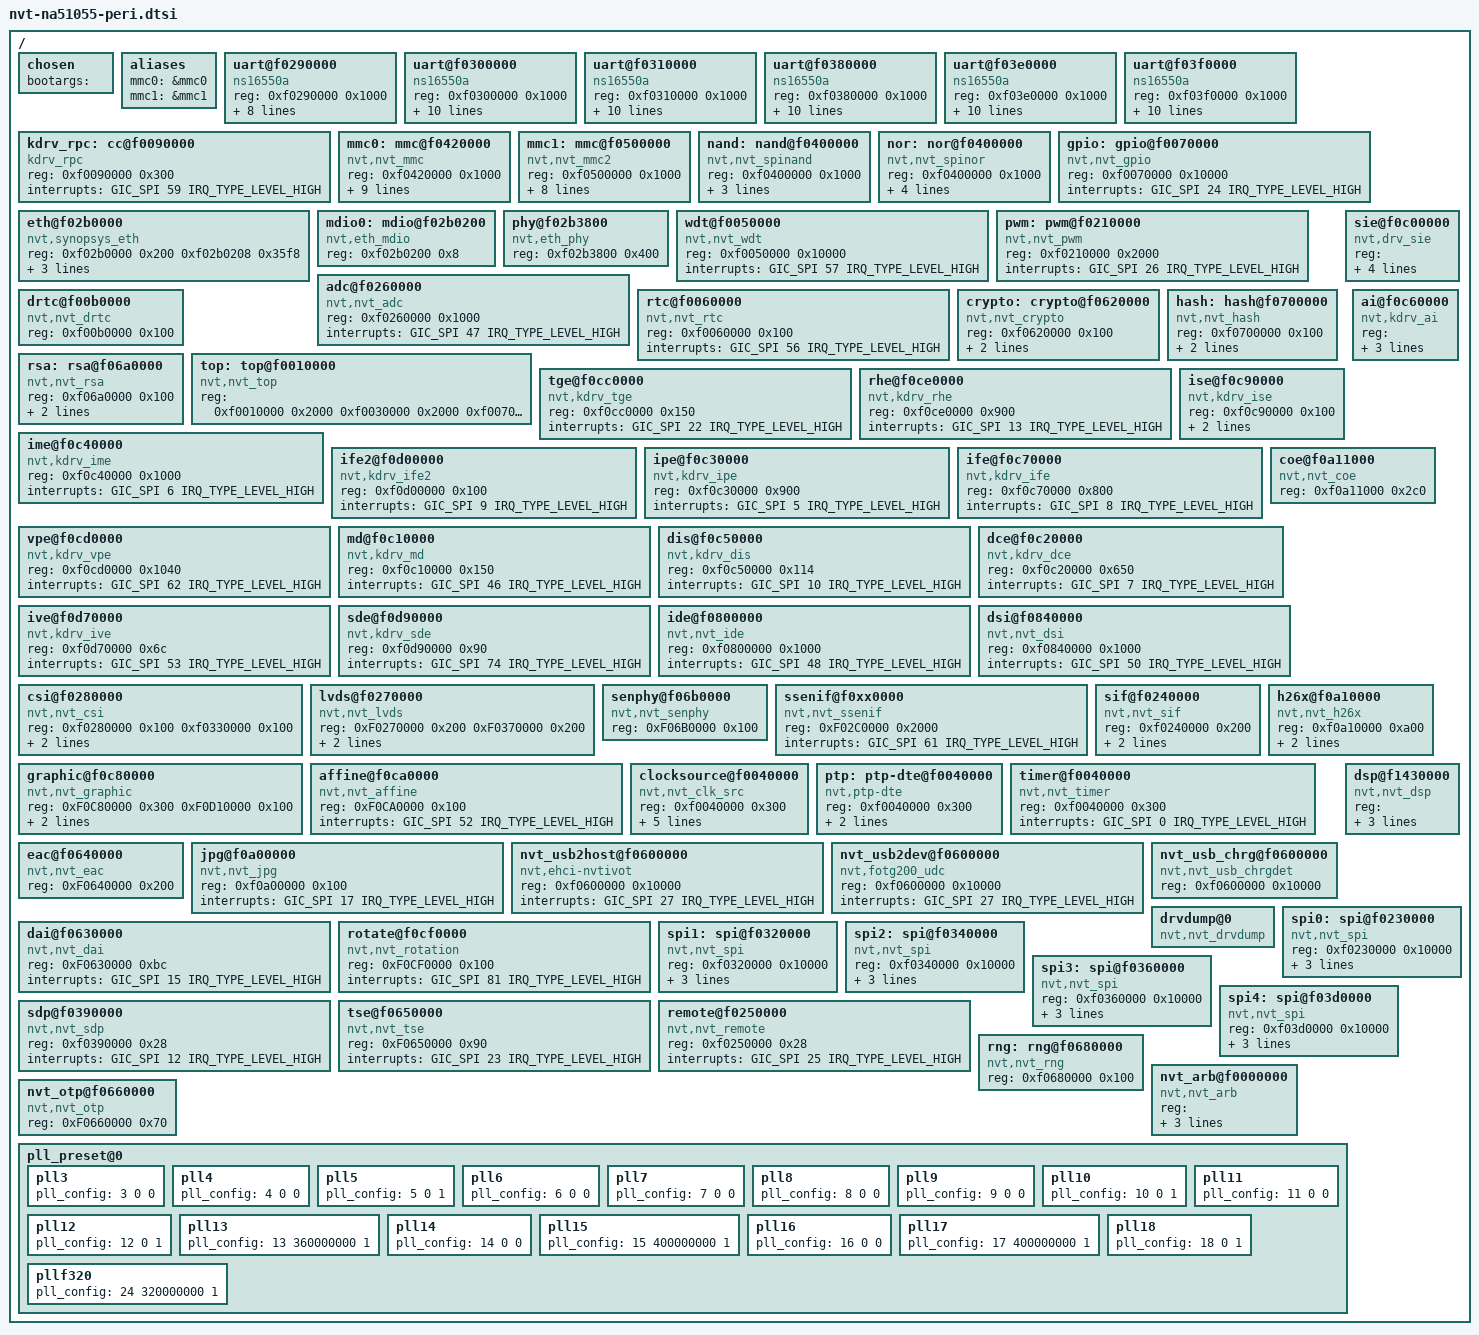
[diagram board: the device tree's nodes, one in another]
/*
 * Novatek Ltd. NA51055 BSP part of dts
 *
 * Cortex-A9
 *
 */


#include <dt-bindings/gpio/nvt-gpio.h>
#include "nvt-na51055-basic.dtsi"

/ {
	chosen {
		bootargs = " ";
	};

	aliases {
		mmc0 = &mmc0;	/* Fixed to mmcblk0 for sdio1 */
		mmc1 = &mmc1;	/* Fixed to mmcblk1 for sdio2 */
	};

	uart@f0290000 {
		compatible = "ns16550a";
		reg = <0xf0290000 0x1000>;
		interrupts = <GIC_SPI 43 IRQ_TYPE_LEVEL_HIGH>;
		baud = <115200>;
		reg-shift = <2>;
		reg-io-width = <4>;
		no-loopback-test = <1>;
		clock-frequency = <24000000>;
		fifo-size = <64>;	/* For platform 520 is 16 and platform 528 is 64 */
		uart_id = <0>;
	};

	uart@f0300000 {
		compatible = "ns16550a";
		reg = <0xf0300000 0x1000>;
		interrupts = <GIC_SPI 44 IRQ_TYPE_LEVEL_HIGH>;
		baud = <115200>;
		reg-shift = <2>;
		reg-io-width = <4>;
		no-loopback-test = <1>;
		clock-frequency = <48000000>;
		fifo-size = <64>;
		hw_flowctrl = <0>;
		rx_trig_level = <1>;
		uart_id = <1>;
	};

	uart@f0310000 {
		compatible = "ns16550a";
		reg = <0xf0310000 0x1000>;
		interrupts = <GIC_SPI 45 IRQ_TYPE_LEVEL_HIGH>;
		baud = <115200>;
		reg-shift = <2>;
		reg-io-width = <4>;
		no-loopback-test = <1>;
		clock-frequency = <48000000>;
		fifo-size = <64>;
		hw_flowctrl = <0>;
		rx_trig_level = <1>;
		uart_id = <2>;
	};

	uart@f0380000 {
		compatible = "ns16550a";
		reg = <0xf0380000 0x1000>;
		interrupts = <GIC_SPI 63 IRQ_TYPE_LEVEL_HIGH>;
		baud = <115200>;
		reg-shift = <2>;
		reg-io-width = <4>;
		no-loopback-test = <1>;
		clock-frequency = <48000000>;
		fifo-size = <64>;
		hw_flowctrl = <0>;
		rx_trig_level = <1>;
		uart_id = <3>;
	};

	uart@f03e0000 {
		compatible = "ns16550a";
		reg = <0xf03e0000 0x1000>;
		interrupts = <GIC_SPI 64 IRQ_TYPE_LEVEL_HIGH>;
		baud = <115200>;
		reg-shift = <2>;
		reg-io-width = <4>;
		no-loopback-test = <1>;
		clock-frequency = <48000000>;
		fifo-size = <64>;
		hw_flowctrl = <0>;
		rx_trig_level = <1>;
		uart_id = <4>;
	};

	uart@f03f0000 {
		compatible = "ns16550a";
		reg = <0xf03f0000 0x1000>;
		interrupts = <GIC_SPI 65 IRQ_TYPE_LEVEL_HIGH>;
		baud = <115200>;
		reg-shift = <2>;
		reg-io-width = <4>;
		no-loopback-test = <1>;
		clock-frequency = <48000000>;
		fifo-size = <64>;
		hw_flowctrl = <0>;
		rx_trig_level = <1>;
		uart_id = <5>;
	};

	kdrv_rpc: cc@f0090000 {
		compatible = "kdrv_rpc";
		reg = <0xf0090000 0x300>;
		interrupts = <GIC_SPI 59 IRQ_TYPE_LEVEL_HIGH>;
	};

	mmc0: mmc@f0420000 {
		compatible = "nvt,nvt_mmc";
		reg = <0xf0420000 0x1000>;
		interrupts = <GIC_SPI 30 IRQ_TYPE_LEVEL_HIGH>;
		max-frequency = <48000000>;
		voltage-switch = <0>;
		max-voltage = <3300>;
		bus-width = <4>;
		neg-sample-edge = <0>;
		driving = <15 15 15 20 15 15 25 25 25 25 25 25>;
		cd_gpio = <P_GPIO(17) GPIO_FALLING_EDGE GPIO_POLLING>;
		/*card_power_gpio = <P_GPIO(0) GPIO_LOW>;*/
		/*ro_gpio = <D_GPIO(1) GPIO_RISING_EDGE GPIO_POLLING>;*/
		/*power_en = <D_GPIO(2) GPIO_RISING_EDGE>;*/
	};

	mmc1: mmc@f0500000 {
		compatible = "nvt,nvt_mmc2";
		reg = <0xf0500000 0x1000>;
		interrupts = <GIC_SPI 31 IRQ_TYPE_LEVEL_HIGH>;
		max-frequency = <48000000>;
		voltage-switch = <0>;
		max-voltage = <3300>;
		bus-width = <4>;
		neg-sample-edge = <0>;
		driving = <15 8 8 15 8 8 15 8 8 15 8 8>;
		cd_gpio = <0 GPIO_FALLING_EDGE GPIO_INTERRUPT>;
		/*ro_gpio = <D_GPIO(3) GPIO_RISING_EDGE GPIO_POLLING>;*/
		/*power_en = <D_GPIO(4) GPIO_RISING_EDGE>;*/
	};

	nand: nand@f0400000 {
		#address-cells = <2>;
		#size-cells = <2>;
		compatible = "nvt,nvt_spinand";
		reg = <0xf0400000 0x1000>;
		interrupts = <GIC_SPI 29 IRQ_TYPE_LEVEL_HIGH>;
		clock-frequency = <80000000>;
		nvt-devname = "spi_nand.0";
	};

	nor: nor@f0400000 {
		#address-cells = <2>;
		#size-cells = <2>;
		compatible = "nvt,nvt_spinor";
		reg = <0xf0400000 0x1000>;
		interrupts = <GIC_SPI 29 IRQ_TYPE_LEVEL_HIGH>;
		clock-frequency = <48000000>;
		nvt-devname = "spi_nor.0";
		trace-stdtable = <1>;
	};

	gpio: gpio@f0070000 {
		compatible = "nvt,nvt_gpio";
		reg = <0xf0070000 0x10000>;
		interrupts = <GIC_SPI 24 IRQ_TYPE_LEVEL_HIGH>;
		#gpio-cells = <2>;
	};

	eth@f02b0000 {
		compatible = "nvt,synopsys_eth";
		reg = <0xf02b0000 0x200
		       0xf02b0208 0x35f8>;
		interrupts = <GIC_SPI 34 IRQ_TYPE_LEVEL_HIGH>;
		sp-clk = <0>;
		ref-clk-out = <0>;
	};

	mdio0: mdio@f02b0200{
		compatible = "nvt,eth_mdio";
		reg = <0xf02b0200 0x8>;
	};

	phy@f02b3800 {
		compatible = "nvt,eth_phy";
		reg = <0xf02b3800 0x400>;
	};

	wdt@f0050000 {
		compatible = "nvt,nvt_wdt";
		reg = <0xf0050000 0x10000>;
		interrupts = <GIC_SPI 57 IRQ_TYPE_LEVEL_HIGH>;
	};

	pwm: pwm@f0210000 {
		compatible = "nvt,nvt_pwm";
		reg = <0xf0210000 0x2000>;
		interrupts = <GIC_SPI 26 IRQ_TYPE_LEVEL_HIGH>;
	};

	adc@f0260000 {
		compatible = "nvt,nvt_adc";
		reg = <0xf0260000 0x1000>;
		interrupts = <GIC_SPI 47 IRQ_TYPE_LEVEL_HIGH>;
		#io-channel-cells = <1>;
	};

	rtc@f0060000 {
		compatible = "nvt,nvt_rtc";
		reg = <0xf0060000 0x100>;
		interrupts = <GIC_SPI 56 IRQ_TYPE_LEVEL_HIGH>;
	};

    drtc@f00b0000 {
        compatible = "nvt,nvt_drtc";
        reg = <0xf00b0000 0x100>;
    };

    crypto: crypto@f0620000 {
        compatible = "nvt,nvt_crypto";
        reg = <0xf0620000 0x100>;
        interrupts = <0 38 IRQ_TYPE_LEVEL_HIGH>;
        mclk = <1>;
    };

    hash: hash@f0700000 {
        compatible = "nvt,nvt_hash";
        reg = <0xf0700000 0x100>;
        interrupts = <0 28 IRQ_TYPE_LEVEL_HIGH>;
        mclk = <1>;
    };

    rsa: rsa@f06a0000 {
        compatible = "nvt,nvt_rsa";
        reg = <0xf06a0000 0x100>;
        interrupts = <0 20 IRQ_TYPE_LEVEL_HIGH>;
        mclk = <1>;
    };

	top: top@f0010000 {
		compatible = "nvt,nvt_top";
		reg = <0xf0010000 0x2000
			0xf0030000 0x2000
			0xf0070000 0x10000>;
	};

	sie@f0c00000 {
		compatible = "nvt,drv_sie";
		reg = <0xf0c00000 0x900
			0xf0d20000 0x900
			0xF0D30000 0x900
			0xF0D40000 0x900
			0xF0D80000 0x900>;
		interrupts = <GIC_SPI 1 IRQ_TYPE_LEVEL_HIGH
					GIC_SPI 2 IRQ_TYPE_LEVEL_HIGH
					GIC_SPI 3 IRQ_TYPE_LEVEL_HIGH
					GIC_SPI 59 IRQ_TYPE_LEVEL_HIGH
					GIC_SPI 61 IRQ_TYPE_LEVEL_HIGH>;
		/*sensor_freq = <37125000>;*/
		power_saving = <0>;  /* 0:using default pll_10,  1: using fix480m, run 240MHz,  2: using fix480m, run 120MHz */
	};

	tge@f0cc0000 {
		compatible = "nvt,kdrv_tge";
		reg = <0xf0cc0000 0x150>;
		interrupts = <GIC_SPI 22 IRQ_TYPE_LEVEL_HIGH>;
	};

	rhe@f0ce0000 {
		compatible = "nvt,kdrv_rhe";
		reg = <0xf0ce0000 0x900>;
		interrupts = <GIC_SPI 13 IRQ_TYPE_LEVEL_HIGH>;
	};

	ime@f0c40000 {
		compatible = "nvt,kdrv_ime";
		reg = <0xf0c40000 0x1000>;
		interrupts = <GIC_SPI 6 IRQ_TYPE_LEVEL_HIGH>;
	};

	ife2@f0d00000 {
		compatible = "nvt,kdrv_ife2";
		reg = <0xf0d00000 0x100>;
		interrupts = <GIC_SPI 9 IRQ_TYPE_LEVEL_HIGH>;
	};

	ise@f0c90000 {
		compatible = "nvt,kdrv_ise";
		reg = <0xf0c90000 0x100>;
		interrupts = <GIC_SPI 21 IRQ_TYPE_LEVEL_HIGH
					GIC_SPI 85 IRQ_TYPE_LEVEL_HIGH>;
	};

	ipe@f0c30000 {
		compatible = "nvt,kdrv_ipe";
		reg = <0xf0c30000 0x900>;
		interrupts = <GIC_SPI 5 IRQ_TYPE_LEVEL_HIGH>;
	};

	ife@f0c70000 {
		compatible = "nvt,kdrv_ife";
		reg = <0xf0c70000 0x800>;
		interrupts = <GIC_SPI 8 IRQ_TYPE_LEVEL_HIGH>;
	};
  
	vpe@f0cd0000 {
		compatible = "nvt,kdrv_vpe";
		reg = <0xf0cd0000 0x1040>;
		interrupts = <GIC_SPI 62 IRQ_TYPE_LEVEL_HIGH>;
	};

	ai@f0c60000 {
		compatible = "nvt,kdrv_ai";
		reg = <0xf0c60000 0x1cc
			   0xf0d50000 0x94
			   0xf0d60000 0x200
			   0xf0cb0000 0x200>;
		interrupts = <GIC_SPI 14 IRQ_TYPE_LEVEL_HIGH
					  GIC_SPI 13 IRQ_TYPE_LEVEL_HIGH
					  GIC_SPI 49 IRQ_TYPE_LEVEL_HIGH
					  GIC_SPI 11 IRQ_TYPE_LEVEL_HIGH>;
    };

	md@f0c10000 {
		compatible = "nvt,kdrv_md";
		reg = <0xf0c10000 0x150>;
		interrupts = <GIC_SPI 46 IRQ_TYPE_LEVEL_HIGH>;
	};
		dis@f0c50000 {
                compatible = "nvt,kdrv_dis";
                reg = <0xf0c50000 0x114>;
                interrupts = <GIC_SPI 10 IRQ_TYPE_LEVEL_HIGH>;
	};

	coe@f0a11000 {
		compatible = "nvt,nvt_coe";
		reg = <0xf0a11000 0x2c0>;
	};

	dce@f0c20000 {
		compatible = "nvt,kdrv_dce";
		reg = <0xf0c20000 0x650>;
		interrupts = <GIC_SPI 7 IRQ_TYPE_LEVEL_HIGH>;
	};

	ive@f0d70000 {
		compatible = "nvt,kdrv_ive";
		reg = <0xf0d70000 0x6c>;
		interrupts = <GIC_SPI 53 IRQ_TYPE_LEVEL_HIGH>;
	};

	sde@f0d90000 {
		compatible = "nvt,kdrv_sde";
		reg = <0xf0d90000 0x90>;
		interrupts = <GIC_SPI 74 IRQ_TYPE_LEVEL_HIGH>;
	};

        ide@f0800000 {
                compatible = "nvt,nvt_ide";
                reg = <0xf0800000 0x1000>;
                interrupts = <GIC_SPI 48 IRQ_TYPE_LEVEL_HIGH>;
        };

	dsi@f0840000 {
		compatible = "nvt,nvt_dsi";
		reg = <0xf0840000 0x1000>;
		interrupts = <GIC_SPI 50 IRQ_TYPE_LEVEL_HIGH>;
	};

	csi@f0280000 {
		compatible = "nvt,nvt_csi";
		reg = <0xf0280000 0x100
				0xf0330000 0x100>;
		interrupts = <GIC_SPI 54 IRQ_TYPE_LEVEL_HIGH
					GIC_SPI 55 IRQ_TYPE_LEVEL_HIGH>;
	};

	lvds@f0270000 {
		compatible = "nvt,nvt_lvds";
		reg = <0xF0270000 0x200
				0xF0370000 0x200>;
		interrupts = <GIC_SPI 54 IRQ_TYPE_LEVEL_HIGH
					GIC_SPI 55 IRQ_TYPE_LEVEL_HIGH>;
	};

	senphy@f06b0000 {
		compatible = "nvt,nvt_senphy";
		reg = <0xF06B0000 0x100>;
	};

	ssenif@f0xx0000 {
		compatible = "nvt,nvt_ssenif";
		reg = <0xF02C0000 0x2000>;
		interrupts = <GIC_SPI 61 IRQ_TYPE_LEVEL_HIGH>;
	};

	sif@f0240000 {
		compatible = "nvt,nvt_sif";
		reg = <0xf0240000 0x200>;
		interrupts = <GIC_SPI 40 IRQ_TYPE_LEVEL_HIGH>;
		clock-frequency = <1000000>;
	};

	graphic@f0c80000 {
		compatible = "nvt,nvt_graphic";
		reg = <0xF0C80000 0x300
			0xF0D10000 0x100>;
		interrupts = <GIC_SPI 18 IRQ_TYPE_LEVEL_HIGH
					GIC_SPI 19 IRQ_TYPE_LEVEL_HIGH>;
	};

	affine@f0ca0000 {
		compatible = "nvt,nvt_affine";
		reg = <0xF0CA0000 0x100>;
		interrupts = <GIC_SPI 52 IRQ_TYPE_LEVEL_HIGH>;
	};

	h26x@f0a10000 {
		compatible = "nvt,nvt_h26x";
		reg = <0xf0a10000 0xa00>;
		interrupts = <GIC_SPI 16 IRQ_TYPE_LEVEL_HIGH>;
		power_saving = <1>;	/* 0:using default pllf320, 1:using pll15, 2:using pll13*/
	};

	clocksource@f0040000 {
		compatible = "nvt,nvt_clk_src";
		reg = <0xf0040000 0x300>;
		interrupts = <GIC_SPI 0 IRQ_TYPE_LEVEL_HIGH>;
		clock-frequency1 = <3000000>;
		clock-frequency2 = <3000000>;
		clksrc = <1>;
		bits = <32>;
		clock-names = "f0040000.timer";
	};

	ptp: ptp-dte@f0040000 {
		compatible = "nvt,ptp-dte";
		reg = <0xf0040000 0x300>;
		clock-frequency = <3000000>;
		interrupts = <GIC_SPI 0 IRQ_TYPE_LEVEL_HIGH>;
	};

	timer@f0040000 {
		compatible = "nvt,nvt_timer";
		reg = <0xf0040000 0x300>;
		interrupts = <GIC_SPI 0 IRQ_TYPE_LEVEL_HIGH>;
	};

	eac@f0640000 {
		compatible = "nvt,nvt_eac";
		reg = <0xF0640000 0x200>;
	};

	jpg@f0a00000 {
		compatible = "nvt,nvt_jpg";
		reg = <0xf0a00000 0x100>;
		interrupts = <GIC_SPI 17 IRQ_TYPE_LEVEL_HIGH>;
	};

	nvt_usb2host@f0600000 {
		compatible = "nvt,ehci-nvtivot";
		reg = <0xf0600000 0x10000>;
		interrupts = <GIC_SPI 27 IRQ_TYPE_LEVEL_HIGH>;
	};

	nvt_usb2dev@f0600000 {
		compatible = "nvt,fotg200_udc";
		reg = <0xf0600000 0x10000>;
		interrupts = <GIC_SPI 27 IRQ_TYPE_LEVEL_HIGH>;
	};

	nvt_usb_chrg@f0600000 {
		compatible = "nvt,nvt_usb_chrgdet";
		reg = <0xf0600000 0x10000>;
	};

	dai@f0630000 {
		compatible = "nvt,nvt_dai";
		reg = <0xF0630000 0xbc>;
		interrupts = <GIC_SPI 15 IRQ_TYPE_LEVEL_HIGH>;
	};

	rotate@f0cf0000 {
		compatible = "nvt,nvt_rotation";
		reg = <0xF0CF0000 0x100>;
		interrupts = <GIC_SPI 81 IRQ_TYPE_LEVEL_HIGH>;
	};

        drvdump@0 {
                compatible = "nvt,nvt_drvdump";
        };

	dsp@f1430000 {
		compatible = "nvt,nvt_dsp";
		reg = <0xF1430000 0x200
			0xF2000000 0x1000000
			0xF1440000 0x200
			0xF3000000 0x1000000>;
		interrupts = <GIC_SPI 76 IRQ_TYPE_LEVEL_HIGH
					GIC_SPI 77 IRQ_TYPE_LEVEL_HIGH>;
	};

	spi0: spi@f0230000 {
		compatible = "nvt,nvt_spi";
		reg = <0xf0230000 0x10000>;
		interrupts = <GIC_SPI 35 IRQ_TYPE_LEVEL_HIGH>;
		dma-support = <0>;
		nvt-devname = <0>;
	};

	spi1: spi@f0320000 {
		compatible = "nvt,nvt_spi";
		reg = <0xf0320000 0x10000>;
		interrupts = <GIC_SPI 36 IRQ_TYPE_LEVEL_HIGH>;
		dma-support = <0>;
		nvt-devname = <1>;
	};

	spi2: spi@f0340000 {
		compatible = "nvt,nvt_spi";
		reg = <0xf0340000 0x10000>;
		interrupts = <GIC_SPI 37 IRQ_TYPE_LEVEL_HIGH>;
		dma-support = <0>;
		nvt-devname = <2>;
	};
	
	spi3: spi@f0360000 {
		compatible = "nvt,nvt_spi";
		reg = <0xf0360000 0x10000>;
		interrupts = <GIC_SPI 66 IRQ_TYPE_LEVEL_HIGH>;
		dma-support = <0>;
		nvt-devname = <3>;		
	};

	spi4: spi@f03d0000 {
		compatible = "nvt,nvt_spi";
		reg = <0xf03d0000 0x10000>;
		interrupts = <GIC_SPI 67 IRQ_TYPE_LEVEL_HIGH>;
		dma-support = <0>;
		nvt-devname = <4>;				
	};

	sdp@f0390000 {
		compatible = "nvt,nvt_sdp";
		reg = <0xf0390000 0x28>;
		interrupts = <GIC_SPI 12 IRQ_TYPE_LEVEL_HIGH>;
	};

	tse@f0650000 {
		compatible = "nvt,nvt_tse";
		reg = <0xF0650000 0x90>;
		interrupts = <GIC_SPI 23 IRQ_TYPE_LEVEL_HIGH>;
	};

	remote@f0250000 {
		compatible = "nvt,nvt_remote";
		reg = <0xf0250000 0x28>;
		interrupts = <GIC_SPI 25 IRQ_TYPE_LEVEL_HIGH>;
	};

        rng: rng@f0680000 {
		compatible = "nvt,nvt_rng";
		reg = <0xf0680000 0x100>;
        };

	nvt_arb@f0000000 {
                compatible = "nvt,nvt_arb";
                reg = <0xF0000000 0xA000
                       0xF0100000 0xA000
                       0xF0FE0000 0x300
                       0xF0FD0000 0x300>;
                interrupts = <GIC_SPI 33 IRQ_TYPE_LEVEL_HIGH
                              GIC_SPI 51 IRQ_TYPE_LEVEL_HIGH>;
	};

	nvt_otp@f0660000 {
                compatible = "nvt,nvt_otp";
                reg = <0xF0660000 0x70>;
	};

        pll_preset@0 {
                pll3{pll_config = <3 0 0>;};
                pll4{pll_config = <4 0 0>;};
                pll5{pll_config = <5 0 1>;};
                pll6{pll_config = <6 0 0>;};
                pll7{pll_config = <7 0 0>;};
                pll8{pll_config = <8 0 0>;};
                pll9{pll_config = <9 0 0>;};
                pll10{pll_config = <10 0 1>;};
                pll11{pll_config = <11 0 0>;};
                pll12{pll_config = <12 0 1>;};
                pll13{pll_config = <13 360000000 1>;};
                pll14{pll_config = <14 0 0>;};
                pll15{pll_config = <15 400000000 1>;};
                pll16{pll_config = <16 0 0>;};
                pll17{pll_config = <17 400000000 1>;};
                pll18{pll_config = <18 0 1>;};
                pllf320{pll_config = <24 320000000 1>;};
        };
};
